# AT32WB415 register map
Vendor: Keil; Series: AT32WB415; File version: 1.0
CPU: CM4 r0p1, little endian, no MPU, FPU, 4 interrupt priority bits
Registers are 32-bit, read-write, reset 0x0 unless marked. A register's access mark holds for its fields unless they carry their own. Offsets are from the block's base; [hi:lo] are bit positions; {n}, {i} and the like mark numbered series; 'fields as' and 'values as' point back to an identical list.

## PWC — Power control
Base 0x40007000
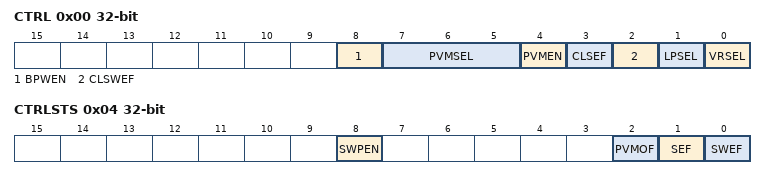
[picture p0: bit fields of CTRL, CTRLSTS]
0x00 CTRL — Power control register (PWC_CTRL)
  [8] BPWEN — Battery powered domain write enable
  [7:5] PVMSEL — Power voltage monitoring boundary select
  [4] PVMEN — Power voltage monitoring enable
  [3] CLSEF — Clear SEF flag
  [2] CLSWEF — Clear SWEF flag
  [1] LPSEL — Low power mode select when Cortex-M4F sleepdeep
  [0] VRSEL — Voltage regulator state select when deepsleep mode
0x04 CTRLSTS — Power control register (PWC_CTRLST)
  [8] SWPEN — Standby wake-up pin enable
  [2] PVMOF ro — Power voltage monitoring output flag
  [1] SEF ro — Standby mode entry flag
  [0] SWEF ro — Standby wake-up event flag

## GPIOA — General purpose IO
Base 0x40010800
Same registers: GPIOB 0x40010C00, GPIOC 0x40011000, GPIOD 0x40011400, GPIOF 0x40011C00
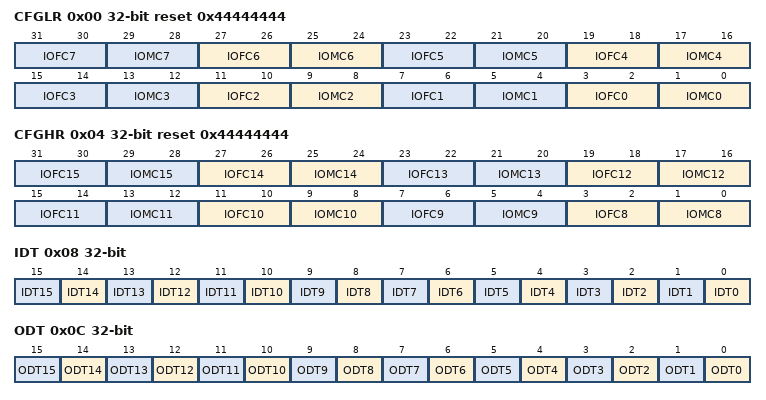
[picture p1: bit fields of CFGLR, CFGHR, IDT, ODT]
0x00 CFGLR reset 0x44444444 — GPIO function configurate low register
  [4n+3:4n+2] IOFC{n} (n=0..7) — Port n.{n} function configurate bits
    0=Analog input; 1=Floating input; 2=PullDownPullUp (Pull-down or pull-up input); 3=MuxOpenDrain (Multiplexed open drain)
  [4n+1:4n] IOMC{n} (n=0..7) — Port n.{n} mode configurate bits
    0=Input mode; 1=OutputLarge (Output mode, large sourcing/sinking strength); 2=Output mode, normal sourcing/sinking strength; 3=OutputMaximum (Output mode, maximum sourcing/sinking strength)
0x04 CFGHR reset 0x44444444 — GPIO function configurate high register
  [4n-29:4n-30] IOFC{n} (n=8..15) — Port n.{n} function configurate bits
    values as CFGLR.IOFC0
  [4n-31:4n-32] IOMC{n} (n=8..15) — Port n.{n} mode configurate bits
    values as CFGLR.IOMC0
0x08 IDT ro — Port input data register
  [n] IDT{n} (n=0..15) — Port input data
    0=Low (Input is logic low); 1=High (Input is logic high)
0x0C ODT — Port output data register
  [n] ODT{n} (n=0..15) — Port output data
    on read: 0=PullDown; 1=PullUp | on write: 0=Low (Set output to logic low); 1=High (Set output to logic high)
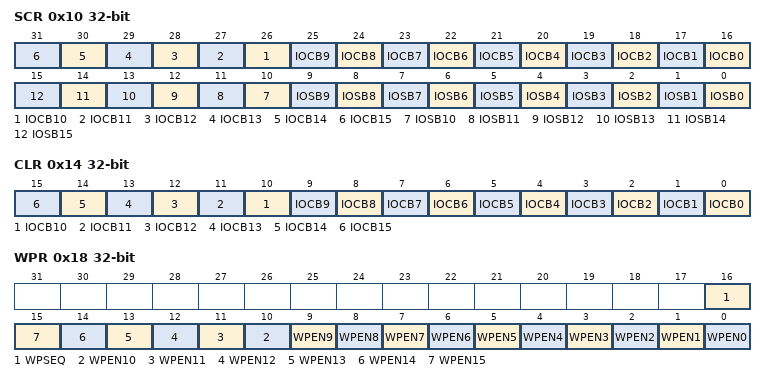
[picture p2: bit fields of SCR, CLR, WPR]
0x10 SCR wo — Port bit set/clear register
  [n+16] IOCB{n} (n=0..15) write-1-clears — Clear bit {n}
    1=Clear the corresponding ODT bit
  [n] IOSB{n} (n=0..15) write-1-sets — Set bit {n}
    1=Set (Set the corresponding ODT bit)
0x14 CLR wo — Port bit reset register
  [n] IOCB{n} (n=0..15) write-1-clears — Clear bit {n}
    1=Clear the corresponding ODT bit
0x18 WPR — Port write protect register
  [16] WPSEQ — Write protect sequence
    0=Clear; 1=Set
  [n] WPEN{n} (n=0..15) — Write protect enable {n}
    on read: 0=NotProtected (Port is not write protected); 1=Protected (Port is write protected) | on write: 0=NoProtect (No effect); 1=Protect (Write protect)

## IOMUX — IO MUX function
Base 0x40010000
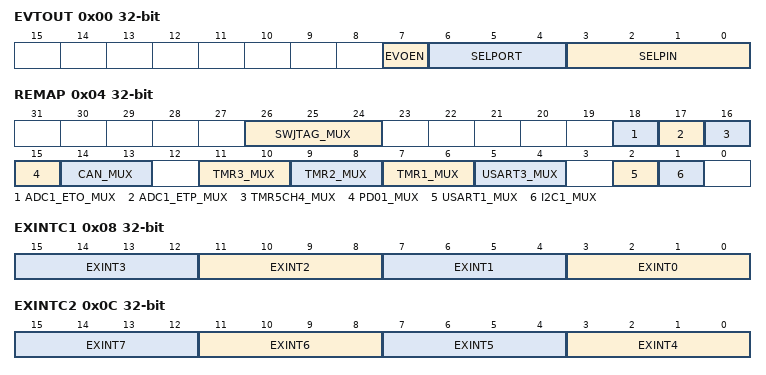
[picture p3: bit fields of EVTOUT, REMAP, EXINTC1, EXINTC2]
0x00 EVTOUT — Event output register (IOMUX_EVTOUT)
  [7] EVOEN — Event output enable
    0=Disable; 1=Enable
  [6:4] SELPORT — Select port
    0=GPIOA; 1=GPIOB; 2=GPIOC; 3=GPIOD; 6=GPIOF
  [3:0] SELPIN — Select pin
0x04 REMAP — IO MUX remap register
  [26:24] SWJTAG_MUX — SWD JTAG muxing
  [18] ADC1_ETO_MUX — ADC1 external trigger ordinary conversion muxing
  [17] ADC1_ETP_MUX — ADC1 external trigger preempted conversion muxing
  [16] TMR5CH4_MUX — TMR5 channel4 internal muxing
  [15] PD01_MUX — PD0/PD1 muxing on OSCIN/OSCOUT
  [14:13] CAN_MUX — CAN1 muxing
  [11:10] TMR3_MUX — TMR3 muxing
  [9:8] TMR2_MUX — TMR2 muxing
  [7:6] TMR1_MUX — TMR1 muxing
  [5:4] USART3_MUX — USART3 muxing
  [2] USART1_MUX — USART1 muxing
  [1] I2C1_MUX — I2C1 muxing
0x08 EXINTC1 — External interrupt configuration register 1 (IOMUX_EXINTC1)
  [4n+3:4n] EXINT{n} (n=0..3) — Configure EXINT{n} source
0x0C EXINTC2 — External interrupt configuration register 2 (IOMUX_EXINTC2)
  [4n-13:4n-16] EXINT{n} (n=4..7) — Configure EXINT{n} source
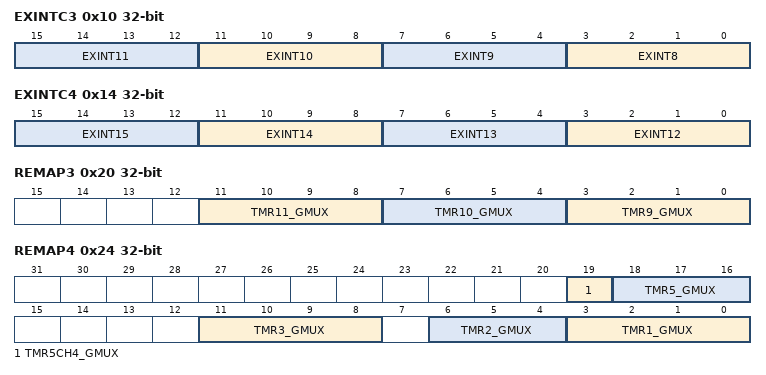
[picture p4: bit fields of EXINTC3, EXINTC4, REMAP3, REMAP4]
0x10 EXINTC3 — External interrupt configuration register 3 (IOMUX_EXINTC3)
  [4n-29:4n-32] EXINT{n} (n=8..11) — Configure EXINT{n} source
0x14 EXINTC4 — External interrupt configuration register 4 (IOMUX_EXINTC4)
  [4n-45:4n-48] EXINT{n} (n=12..15) — Configure EXINT{n} source
0x1C REMAP2 wo — IO MUX remap register 2
  [27:26] CMP_MUX — CMP internal muxing
0x20 REMAP3 — IO MUX remap register 3
  [11:8] TMR11_GMUX — TMR11 muxing
  [7:4] TMR10_GMUX — TMR10 muxing
  [3:0] TMR9_GMUX — TMR9 muxing
0x24 REMAP4 — IO MUX remap register 4
  [19] TMR5CH4_GMUX — TMR5CH4 muxing
  [18:16] TMR5_GMUX — TMR5 muxing
  [11:8] TMR3_GMUX — TMR3 muxing
  [6:4] TMR2_GMUX — TMR2 muxing
  [3:0] TMR1_GMUX — TMR1 muxing
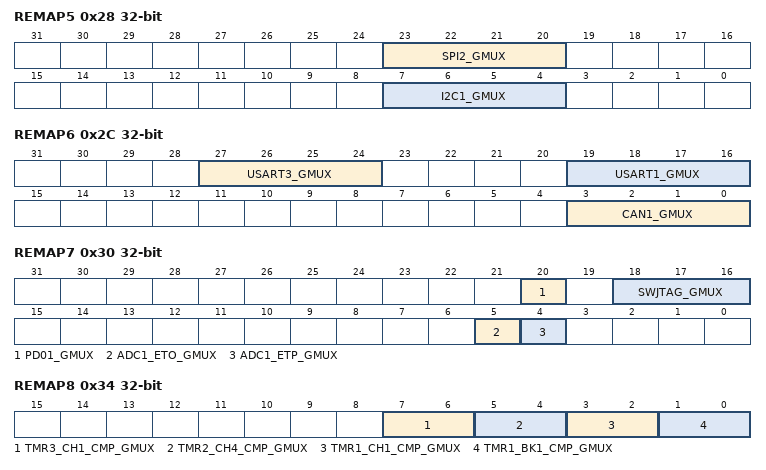
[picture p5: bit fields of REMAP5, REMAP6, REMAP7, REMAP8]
0x28 REMAP5 — IO MUX remap register 5
  [23:20] SPI2_GMUX — SPI2 muxing
  [7:4] I2C1_GMUX — I2C1 muxing
0x2C REMAP6 — IO MUX remap register 6
  [27:24] USART3_GMUX — USART3 muxing
  [19:16] USART1_GMUX — USART1 muxing
  [3:0] CAN1_GMUX — CAN1 muxing
0x30 REMAP7 — IO MUX remap register 7
  [20] PD01_GMUX — PortD0/PortD1 muxing on OSC_IN/OSC_OUT
  [18:16] SWJTAG_GMUX — Serial wire JTAG muxing
  [5] ADC1_ETO_GMUX — ADC1 external trigger ordinary conversion muxing
  [4] ADC1_ETP_GMUX — ADC1 external trigger preempted conversion muxing
0x34 REMAP8 — IO MUX remap register 8
  [7:6] TMR3_CH1_CMP_GMUX — TMR3 CH1 CMP muxing
  [5:4] TMR2_CH4_CMP_GMUX — TMR2 CH4 CMP muxing
  [3:2] TMR1_CH1_CMP_GMUX — TMR1 CH1 CMP muxing
  [1:0] TMR1_BK1_CMP_GMUX — TMR1 BK1 CMP muxing
